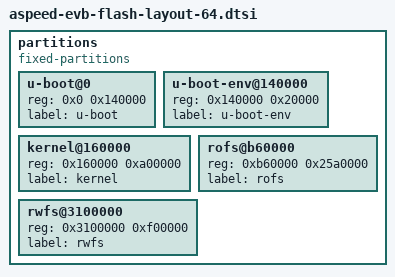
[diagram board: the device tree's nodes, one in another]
// SPDX-License-Identifier: GPL-2.0+
/*
 * Copyright (C) 2023 ASPEED.
 */

partitions {
	compatible = "fixed-partitions";
	#address-cells = <1>;
	#size-cells = <1>;

	u-boot@0 {
		reg = <0x0 0x140000>; // 1280KB
		label = "u-boot";
	};

	u-boot-env@140000 {
		reg = <0x140000 0x20000>; // 128KB
		label = "u-boot-env";
	};

	kernel@160000 {
		reg = <0x160000 0xa00000>; // 10MB
		label = "kernel";
	};

	rofs@b60000 {
		reg = <0xb60000 0x25a0000>; // 37.625MB
		label = "rofs";
	};

	rwfs@3100000 {
		reg = <0x3100000 0xf00000>; // 15MB
		label = "rwfs";
	};
};
